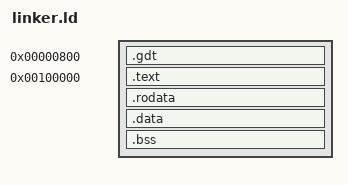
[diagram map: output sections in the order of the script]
ENTRY(_start)

SECTIONS
{
    /* GDT at address 0x00000800 */
    .gdt 0x00000800 :
    {
        KEEP(*(.gdt))
    }
	. = 1M;
	.text BLOCK(4K) : ALIGN(4K)
	{
		*(.multiboot)
		*(.text)
	}

	/* Read-only data. */
	.rodata BLOCK(4K) : ALIGN(4K)
	{
		*(.rodata)
	}

	/* Read-write data (initialized) */
	.data BLOCK(4K) : ALIGN(4K)
	{
		*(.data)
	}

	/* Read-write data (uninitialized) and stack */
	.bss BLOCK(4K) : ALIGN(4K)
	{
		*(COMMON)
		*(.bss)
	}
}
